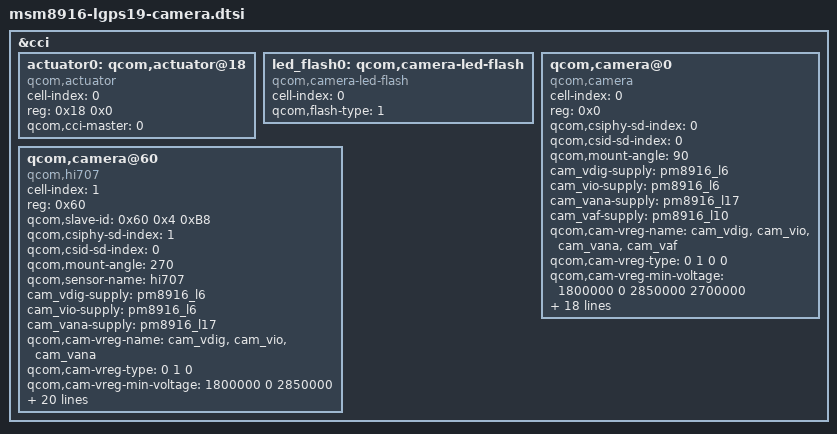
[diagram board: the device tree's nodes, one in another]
/*
 * Copyright (c) 2013, The Linux Foundation. All rights reserved.
 *
 * This program is free software; you can redistribute it and/or modify
 * it under the terms of the GNU General Public License version 2 and
 * only version 2 as published by the Free Software Foundation.
 *
 * This program is distributed in the hope that it will be useful,
 * but WITHOUT ANY WARRANTY; without even the implied warranty of
 * MERCHANTABILITY or FITNESS FOR A PARTICULAR PURPOSE.  See the
 * GNU General Public License for more details.
 */

&cci {
	actuator0: qcom,actuator@18 {
		cell-index = <0>;	//Use Af_main_0 of dw9716 with HI544
		reg = <0x18 0x0>;
		compatible = "qcom,actuator";
		qcom,cci-master = <0>;
	};

	led_flash0: qcom,camera-led-flash {
		cell-index = <0>;
		compatible = "qcom,camera-led-flash";
		qcom,flash-type = <1>;
		//qcom,flash-source = <&pm8226_flash0>;
        //qcom,torch-source = <&pm8226_torch>;
	};
/*
	eeprom0: qcom,eeprom@28 { //EEPROM READ
		cell-index = <1>;
		reg = <0x28 0x0>;
		qcom,eeprom-name = "hi544_eeprom";
		compatible = "qcom,eeprom";
		qcom,slave-addr = <0x28>;
		qcom,cci-master = <0>;

		qcom,cam-power-seq-type = "sensor_gpio","sensor_gpio";
		qcom,cam-power-seq-val = "sensor_gpio_vio","sensor_gpio_standby";
		qcom,cam-power-seq-cfg-val = <1 1>;
		qcom,cam-power-seq-delay = <1 1>;
		qcom,gpio-no-mux = <0>;
		gpios = <&msm_gpio 113 0>,	//1.8V IOVDD
			<&msm_gpio 36 0>;		//2.8V VCM
		qcom,gpio-vio = <1>;
		qcom,gpio-standby = <0>;		//CAM_STANDBY
		qcom,gpio-req-tbl-num = <0 1>;
		qcom,gpio-req-tbl-flags = <0 0>;
		qcom,gpio-req-tbl-label = "MAIN_VIO_EN","CAM_STANDBY";

		qcom,num-blocks = <1>;
		qcom,page0 = <0 0x0 1 0x0 1 20>; // valid size, addr, addr_t, data, data_t, delay
		qcom,poll0 = <0 0x0 1 0x0 1 20>;
		qcom,mem0  = <0x06 0x0000 2 0 1 0>; //EEPROM READ
		revision = "rev_b..."; // EEPROM READ from rev b
	};

	hi544:qcom,camera@40 {


		compatible = "qcom,hi544";
		reg = <0x40 0x0>;
		qcom,slave-id = <0x40 0x0F16 0x4405>;  //0x0544 is expected but real sensor's order is swiched
		qcom,csiphy-sd-index = <0>;
		qcom,csid-sd-index = <0>;
		qcom,mount-angle = <90>;
		qcom,sensor-name = "hi544";
		
		cam_vdig-supply = <&pm8916_l6>;
		cam_vio-supply = <&pm8916_l6>;
		cam_vana-supply = <&pm8916_l17>;
		cam_vaf-supply = <&pm8916_l10>;
		qcom,cam-vreg-name = "cam_vdig", "cam_vio", "cam_vana",
							"cam_vaf";
		qcom,cam-vreg-type = <0 1 0 0>;
		qcom,cam-vreg-min-voltage = <1800000 0 2850000 2700000>;
		qcom,cam-vreg-max-voltage = <1800000 0 2850000 2700000>;
		qcom,cam-vreg-op-mode = <200000 0 80000 100000>;

		pinctrl-names = "cam_default", "cam_suspend";
		pinctrl-0 = <&cam_sensor_mclk0_default
				&cam_sensor_rear_default>;
		pinctrl-1 = <&cam_sensor_mclk0_sleep &cam_sensor_rear_sleep>;

		gpios = <&msm_gpio 26 0>,	//MAIN_CAM0_MCLK
			<&msm_gpio 35 0>;		//MAIN_CAM0_RESET_N

		qcom,gpio-reset = <1>;

		qcom,gpio-req-tbl-num = <0 1>;
		qcom,gpio-req-tbl-flags = <1 0>;
		qcom,gpio-req-tbl-label = "CAMIF_MCLK", "CAM_RESET1";

		qcom,csi-lane-assign = <0x4320>;
		qcom,csi-lane-mask = <0x07>;
		qcom,sensor-position = <0>;
		qcom,sensor-mode = <1>;
		qcom,cci-master = <0>;

		
		clocks = <&clock_gcc clk_mclk0_clk_src>,
				<&clock_gcc clk_gcc_camss_mclk0_clk>;
		clock-names = "cam_src_clk", "cam_clk";

	};
*/
	qcom,camera@0 {
		cell-index = <0>;
		compatible = "qcom,camera";
		reg = <0x0>;
		qcom,csiphy-sd-index = <0>;
		qcom,csid-sd-index = <0>;
		qcom,mount-angle = <90>;
		//qcom,actuator-src = <&actuator0>;
		//qcom,led-flash-src = <&led_flash0>;
		cam_vdig-supply = <&pm8916_l6>;
		cam_vio-supply = <&pm8916_l6>;
		cam_vana-supply = <&pm8916_l17>;
		cam_vaf-supply = <&pm8916_l10>;
		qcom,cam-vreg-name = "cam_vdig", "cam_vio", "cam_vana",
							"cam_vaf";
		qcom,cam-vreg-type = <0 1 0 0>;
		qcom,cam-vreg-min-voltage = <1800000 0 2850000 2700000>;
		qcom,cam-vreg-max-voltage = <1800000 0 2850000 2700000>;
		qcom,cam-vreg-op-mode = <200000 0 80000 100000>;

		pinctrl-names = "cam_default", "cam_suspend";
		pinctrl-0 = <&cam_sensor_mclk0_default
				&cam_sensor_rear_default>;
		pinctrl-1 = <&cam_sensor_mclk0_sleep &cam_sensor_rear_sleep>;
		gpios = <&msm_gpio 26 0>,	//MAIN_CAM0_MCLK
			<&msm_gpio 35 0>;		//MAIN_CAM0_RESET_N

		qcom,gpio-reset = <1>;

		qcom,gpio-req-tbl-num = <0 1>;
		qcom,gpio-req-tbl-flags = <1 0>;
		qcom,gpio-req-tbl-label = "CAMIF_MCLK", "CAM_RESET1";

		qcom,sensor-position = <0>;
		qcom,sensor-mode = <1>;
		qcom,cci-master = <0>;

		status = "ok";
		clocks = <&clock_gcc clk_mclk0_clk_src>,
				<&clock_gcc clk_gcc_camss_mclk0_clk>;
		clock-names = "cam_src_clk", "cam_clk";
	};

	qcom,camera@60 {

		cell-index = <1>;
		
		compatible = "qcom,hi707";
		reg = <0x60>;
		qcom,slave-id = <0x60 0x4 0xB8>;
		qcom,csiphy-sd-index = <1>;
		qcom,csid-sd-index = <0>;
		qcom,mount-angle = <270>;
		qcom,sensor-name = "hi707";

		cam_vdig-supply = <&pm8916_l6>;
		cam_vio-supply = <&pm8916_l6>;
		cam_vana-supply = <&pm8916_l17>;
		
		qcom,cam-vreg-name = "cam_vdig", "cam_vio", "cam_vana";
		qcom,cam-vreg-type = <0 1 0>;
		qcom,cam-vreg-min-voltage = <1800000 0 2850000>;
		qcom,cam-vreg-max-voltage = <1800000 0 2850000>;
		qcom,cam-vreg-op-mode = <200000 0 80000>;
		pinctrl-names = "cam_default", "cam_suspend";
		pinctrl-0 = <&cam_sensor_mclk1_default &cam_sensor_front_default>;
		pinctrl-1 = <&cam_sensor_mclk1_sleep &cam_sensor_front_sleep>;

		//qcom,gpio-no-mux = <0>;
		gpios = <&msm_gpio 27 0>,	//VT_CAM_MCLK
			<&msm_gpio 28 0>,		//VT_CAM_RESET_N, GPIO 28
			<&msm_gpio 33 0>;	//VT_CAM_PWDN, GPIO=33
			
		qcom,gpio-reset = <1>;
		qcom,gpio-standby = <2>;

		qcom,gpio-req-tbl-num = <0 1 2>;
		qcom,gpio-req-tbl-flags = <1 0 0>;
		qcom,gpio-req-tbl-label = "CAMIF_MCLK2", "CAM_RESET2", "CAM_STANDBY2";
		qcom,csi-lane-assign = <0x4320>;
		qcom,csi-lane-mask = <0x3>;
		qcom,sensor-position = <1>;
		qcom,sensor-mode = <1>;
		qcom,cci-master = <0>;

		clocks = <&clock_gcc clk_mclk1_clk_src>,
				<&clock_gcc clk_gcc_camss_mclk1_clk>;
		clock-names = "cam_src_clk", "cam_clk";

	};

};
